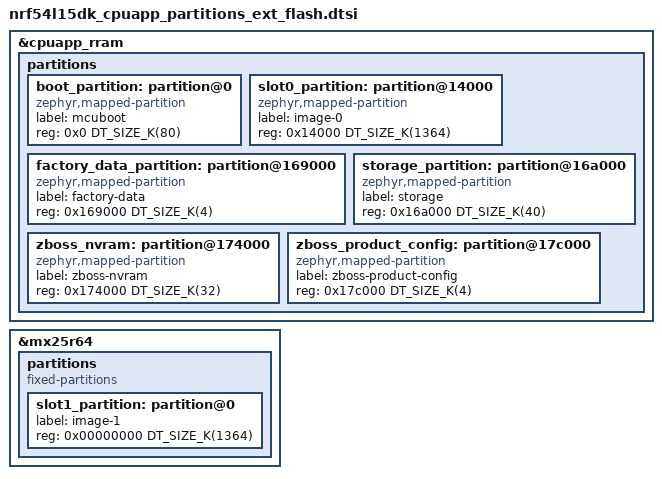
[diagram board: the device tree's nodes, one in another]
/*
 * Copyright (c) 2026 Nordic Semiconductor ASA
 *
 * SPDX-License-Identifier: LicenseRef-Nordic-5-Clause
 */

/delete-node/ &boot_partition;
/delete-node/ &slot0_partition;
/delete-node/ &slot1_partition;
/delete-node/ &storage_partition;

&cpuapp_rram {
	partitions {
		boot_partition: partition@0 {
			compatible = "zephyr,mapped-partition";
			label = "mcuboot";
			reg = <0x0 DT_SIZE_K(80)>;
		};

		slot0_partition: partition@14000 {
			compatible = "zephyr,mapped-partition";
			label = "image-0";
			reg = <0x14000 DT_SIZE_K(1364)>;
		};

		factory_data_partition: partition@169000 {
			compatible = "zephyr,mapped-partition";
			label = "factory-data";
			reg = <0x169000 DT_SIZE_K(4)>;
		};

		storage_partition: partition@16a000 {
			compatible = "zephyr,mapped-partition";
			label = "storage";
			reg = <0x16a000 DT_SIZE_K(40)>;
		};

		zboss_nvram: partition@174000 {
			compatible = "zephyr,mapped-partition";
			label = "zboss-nvram";
			reg = <0x174000 DT_SIZE_K(32)>;
		};

		zboss_product_config: partition@17c000 {
			compatible = "zephyr,mapped-partition";
			label = "zboss-product-config";
			reg = <0x17c000 DT_SIZE_K(4)>;
		};
	};
};

&mx25r64 {
	status = "okay";

	partitions {
		compatible = "fixed-partitions";
		#address-cells = <1>;
		#size-cells = <1>;

		slot1_partition: partition@0 {
			label = "image-1";
			reg = <0x00000000 DT_SIZE_K(1364)>;
		};
	};
};
